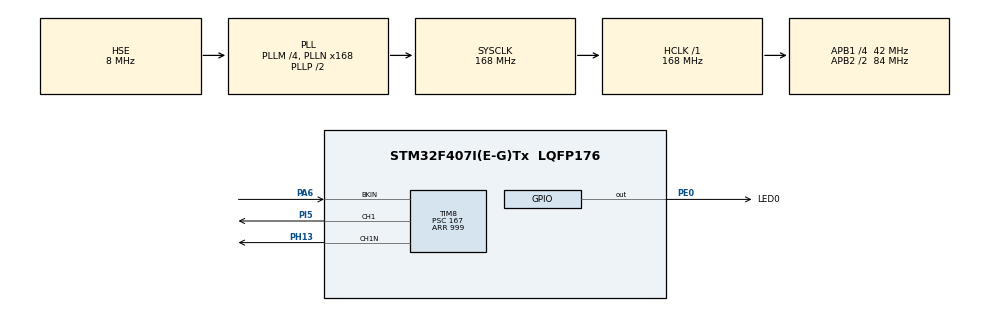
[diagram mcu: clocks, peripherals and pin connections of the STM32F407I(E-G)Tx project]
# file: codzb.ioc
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Mcu.Family=STM32F4
Mcu.Name=STM32F407I(E-G)Tx
Mcu.Package=LQFP176
NVIC.PriorityGroup=NVIC_PRIORITYGROUP_4
PA13.Mode=Serial_Wire
PA13.Signal=SYS_JTMS-SWDIO
PA14.Mode=Serial_Wire
PA14.Signal=SYS_JTCK-SWCLK
PA6.GPIO_PuPd=GPIO_PULLUP
PA6.Mode=Activate-Break-Input
PA6.Signal=TIM8_BKIN
PE0.GPIO_Label=LED0
PE0.GPIO_Speed=GPIO_SPEED_FREQ_MEDIUM
PE0.PinState=GPIO_PIN_SET
PE0.Signal=GPIO_Output
PH0-OSC_IN.Mode=HSE-External-Oscillator
PH0-OSC_IN.Signal=RCC_OSC_IN
PH1-OSC_OUT.Mode=HSE-External-Oscillator
PH1-OSC_OUT.Signal=RCC_OSC_OUT
PH13.GPIO_Speed=GPIO_SPEED_FREQ_VERY_HIGH
PH13.Mode=PWM Generation1 CH1 CH1N
PH13.Signal=TIM8_CH1N
PI5.GPIO_Speed=GPIO_SPEED_FREQ_VERY_HIGH
PI5.Signal=S_TIM8_CH1
ProjectManager.HeapSize=0x200
ProjectManager.StackSize=0x400
ProjectManager.TargetToolchain=MDK-ARM V5
RCC.48MHZClocksFreq_Value=84000000
RCC.AHBFreq_Value=168000000
RCC.APB1CLKDivider=RCC_HCLK_DIV4
RCC.APB1Freq_Value=42000000
RCC.APB1TimFreq_Value=84000000
RCC.APB2CLKDivider=RCC_HCLK_DIV2
RCC.APB2Freq_Value=84000000
RCC.APB2TimFreq_Value=168000000
RCC.CortexFreq_Value=168000000
RCC.HCLKFreq_Value=168000000
RCC.HSE_VALUE=8000000
RCC.HSI_VALUE=16000000
RCC.LSE_VALUE=32768
RCC.PLLM=4
RCC.PLLN=168
RCC.PLLSourceVirtual=RCC_PLLSOURCE_HSE
RCC.SYSCLKFreq_VALUE=168000000
RCC.SYSCLKSource=RCC_SYSCLKSOURCE_PLLCLK
RCC.VCOOutputFreq_Value=336000000
SH.S_TIM8_CH1.0=TIM8_CH1,PWM Generation1 CH1 CH1N
TIM8.AutoReloadPreload=TIM_AUTORELOAD_PRELOAD_ENABLE
TIM8.AutomaticOutput=TIM_AUTOMATICOUTPUT_ENABLE
TIM8.BreakPolarity=TIM_BREAKPOLARITY_LOW
TIM8.Channel-PWM\ Generation1\ CH1\ CH1N=TIM_CHANNEL_1
TIM8.ClockDivision=TIM_CLOCKDIVISION_DIV4
TIM8.DeadTime=100
TIM8.OCNPolarity_1=TIM_OCNPOLARITY_LOW
TIM8.OCPolarity_1=TIM_OCPOLARITY_LOW
TIM8.Period=999
TIM8.Prescaler=167
TIM8.Pulse-PWM\ Generation1\ CH1\ CH1N=500
VP_TIM8_VS_ClockSourceINT.Mode=Internal
board=custom

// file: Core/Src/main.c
/* USER CODE BEGIN Header */
/**
 * @file    main.c
 * @brief   TIM8 PWM互补输出 + 刹车演示 - 主程序
 * @note    硬件平台: STM32F407IGT6
 *          PI5  -> TIM8_CH1  (PWM输出)     -> 示波器CH1
 *          PH13 -> TIM8_CH1N (互补输出)    -> 示波器CH2
 *          PA6  -> TIM8_BKIN (刹车输入)    -> 低电平触发刹车
 */
/* USER CODE END Header */
#include "main.h"
#include "tim.h"
#include "gpio.h"

void SystemClock_Config(void);

int main(void)
{

  /* MCU Configuration--------------------------------------------------------*/

  /* Reset of all peripherals, Initializes the Flash interface and the Systick. */
  HAL_Init();

  /* Configure the system clock */
  SystemClock_Config();

  /* Initialize all configured peripherals */
  MX_GPIO_Init();
  MX_TIM8_Init();
  /* USER CODE BEGIN 2 */
  HAL_TIM_PWM_Start(&htim8, TIM_CHANNEL_1);
  HAL_TIMEx_PWMN_Start(&htim8, TIM_CHANNEL_1);
  /* USER CODE END 2 */

  /* Infinite loop */
  while (1)
  {

    /* USER CODE BEGIN 3 */
		HAL_GPIO_TogglePin(LED0_GPIO_Port, LED0_Pin);
		HAL_Delay(1000);
  }
  /* USER CODE END 3 */
}

void SystemClock_Config(void)
{
  RCC_OscInitTypeDef RCC_OscInitStruct = {0};
  RCC_ClkInitTypeDef RCC_ClkInitStruct = {0};

  /** Configure the main internal regulator output voltage
  */
  __HAL_RCC_PWR_CLK_ENABLE();
  __HAL_PWR_VOLTAGESCALING_CONFIG(PWR_REGULATOR_VOLTAGE_SCALE1);

  /** Initializes the RCC Oscillators according to the specified parameters
  * in the RCC_OscInitTypeDef structure.
  */
  RCC_OscInitStruct.OscillatorType = RCC_OSCILLATORTYPE_HSE;
  RCC_OscInitStruct.HSEState = RCC_HSE_ON;
  RCC_OscInitStruct.PLL.PLLState = RCC_PLL_ON;
  RCC_OscInitStruct.PLL.PLLSource = RCC_PLLSOURCE_HSE;
  RCC_OscInitStruct.PLL.PLLM = 4;
  RCC_OscInitStruct.PLL.PLLN = 168;
  RCC_OscInitStruct.PLL.PLLP = RCC_PLLP_DIV2;
  RCC_OscInitStruct.PLL.PLLQ = 4;
  if (HAL_RCC_OscConfig(&RCC_OscInitStruct) != HAL_OK)
  {
    Error_Handler();
  }

  /** Initializes the CPU, AHB and APB buses clocks
  */
  RCC_ClkInitStruct.ClockType = RCC_CLOCKTYPE_HCLK|RCC_CLOCKTYPE_SYSCLK
                              |RCC_CLOCKTYPE_PCLK1|RCC_CLOCKTYPE_PCLK2;
  RCC_ClkInitStruct.SYSCLKSource = RCC_SYSCLKSOURCE_PLLCLK;
  RCC_ClkInitStruct.AHBCLKDivider = RCC_SYSCLK_DIV1;
  RCC_ClkInitStruct.APB1CLKDivider = RCC_HCLK_DIV4;
  RCC_ClkInitStruct.APB2CLKDivider = RCC_HCLK_DIV2;

  if (HAL_RCC_ClockConfig(&RCC_ClkInitStruct, FLASH_LATENCY_5) != HAL_OK)
  {
    Error_Handler();
  }
}

void Error_Handler(void)
{
  __disable_irq();
  while (1)
  {
  }
}
